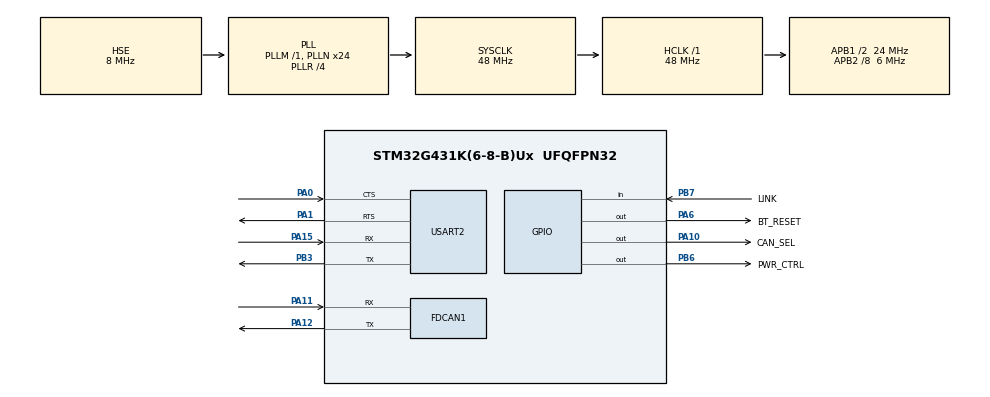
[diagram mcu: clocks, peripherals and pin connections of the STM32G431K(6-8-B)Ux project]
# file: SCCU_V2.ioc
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FDCAN1.AutoRetransmission=ENABLE
FDCAN1.CalculateBaudRateNominal=2000000
FDCAN1.CalculateTimeBitNominal=500
FDCAN1.CalculateTimeQuantumNominal=20.833333333333332
FDCAN1.ClockDivider=FDCAN_CLOCK_DIV4
FDCAN1.DataSyncJumpWidth=4
FDCAN1.DataTimeSeg1=18
FDCAN1.DataTimeSeg2=5
FDCAN1.NominalPrescaler=1
FDCAN1.NominalSyncJumpWidth=4
FDCAN1.NominalTimeSeg1=18
FDCAN1.NominalTimeSeg2=5
FDCAN1.StdFiltersNbr=4
Mcu.Family=STM32G4
Mcu.Name=STM32G431K(6-8-B)Ux
Mcu.Package=UFQFPN32
NVIC.FDCAN1_IT0_IRQn=true\:0\:0\:false\:false\:true\:true\:true\:true
NVIC.FDCAN1_IT1_IRQn=true\:0\:0\:false\:false\:true\:true\:true\:true
NVIC.PriorityGroup=NVIC_PRIORITYGROUP_4
NVIC.USART2_IRQn=true\:0\:0\:false\:false\:true\:true\:true\:true
PA0.Mode=CTS_RTS
PA0.Signal=USART2_CTS
PA1.Mode=CTS_RTS
PA1.Signal=USART2_RTS
PA10.GPIO_Label=CAN_SEL
PA10.Signal=GPIO_Output
PA11.Mode=FDCAN_Activate
PA11.Signal=FDCAN1_RX
PA12.Mode=FDCAN_Activate
PA12.Signal=FDCAN1_TX
PA15.Mode=Asynchronous
PA15.Signal=USART2_RX
PA2.Mode=SYS_WakeUp3
PA2.Signal=SYS_WKUP4
PA6.GPIO_Label=BT_RESET
PA6.Signal=GPIO_Output
PB3.Mode=Asynchronous
PB3.Signal=USART2_TX
PB6.GPIO_Label=PWR_CTRL
PB6.Signal=GPIO_Output
PB7.GPIO_Label=LINK
PB7.Signal=GPIO_Input
PF0-OSC_IN.Mode=HSE-External-Oscillator
PF0-OSC_IN.Signal=RCC_OSC_IN
PF1-OSC_OUT.Mode=HSE-External-Oscillator
PF1-OSC_OUT.Signal=RCC_OSC_OUT
ProjectManager.HeapSize=0x200
ProjectManager.StackSize=0x400
ProjectManager.TargetToolchain=STM32CubeIDE
RCC.ADC12Freq_Value=48000000
RCC.AHBFreq_Value=48000000
RCC.APB1CLKDivider=RCC_HCLK_DIV2
RCC.APB1Freq_Value=24000000
RCC.APB1TimFreq_Value=48000000
RCC.APB2CLKDivider=RCC_HCLK_DIV8
RCC.APB2Freq_Value=6000000
RCC.APB2TimFreq_Value=12000000
RCC.CortexFreq_Value=48000000
RCC.EXTERNAL_CLOCK_VALUE=12288000
RCC.FDCANCLockSelection=RCC_FDCANCLKSOURCE_PLL
RCC.HCLKFreq_Value=48000000
RCC.HSE_VALUE=8000000
RCC.HSI48_VALUE=48000000
RCC.HSI_VALUE=16000000
RCC.LSE_VALUE=32768
RCC.PLLN=24
RCC.PLLQ=RCC_PLLQ_DIV4
RCC.PLLR=RCC_PLLR_DIV4
RCC.PLLSourceVirtual=RCC_PLLSOURCE_HSE
RCC.PWR_Regulator_Voltage_Scale=PWR_REGULATOR_VOLTAGE_SCALE1
RCC.SYSCLKFreq_VALUE=48000000
RCC.SYSCLKSource=RCC_SYSCLKSOURCE_PLLCLK
RCC.USART2CLockSelection=RCC_USART2CLKSOURCE_SYSCLK
RCC.USBFreq_Value=48000000
RCC.VCOOutputFreq_Value=192000000
USART2.VirtualMode-Asynchronous=VM_ASYNC
VP_SYS_VS_DBSignals.Mode=DisableDeadBatterySignals
VP_WWDG_VS_WWDG.Mode=WWDG_Activate
WWDG.Counter=127
WWDG.Prescaler=WWDG_PRESCALER_128
WWDG.Window=127
board=custom

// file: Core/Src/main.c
/* USER CODE BEGIN Header */
/**
  ******************************************************************************
  * @file           : main.c
  * @brief          : Main program body
  ******************************************************************************
  * @attention
  *
  * Copyright (c) 2022 STMicroelectronics.
  * All rights reserved.
  *
  * This software is licensed under terms that can be found in the LICENSE file
  * in the root directory of this software component.
  * If no LICENSE file comes with this software, it is provided AS-IS.
  *
  ******************************************************************************
  */
/* USER CODE END Header */
#include "main.h"
#include "fdcan.h"
#include "usart.h"
#include "wwdg.h"
#include "gpio.h"

/* USER CODE BEGIN Includes */

#include "stdbool.h"
#include "../../Application/mainTask.h"
#include "../../Application/Modules/Modules.h"

/* USER CODE END Includes */

void SystemClock_Config(void);

int main(void)
{
  /* USER CODE BEGIN 1 */

  RTT_INIT("RTT init\n");

  /* USER CODE END 1 */

  /* MCU Configuration--------------------------------------------------------*/

  /* Reset of all peripherals, Initializes the Flash interface and the Systick. */
  HAL_Init();

  /* Configure the system clock */
  SystemClock_Config();

  /* Initialize all configured peripherals */
  MX_GPIO_Init();
  MX_FDCAN1_Init();
  MX_USART2_UART_Init();
  MX_WWDG_Init();

  /* Infinite loop */
  while (1)
  {

    /* USER CODE BEGIN 3 */
    mainTask();
  }
  /* USER CODE END 3 */
}

void SystemClock_Config(void)
{
  RCC_OscInitTypeDef RCC_OscInitStruct = {0};
  RCC_ClkInitTypeDef RCC_ClkInitStruct = {0};

  /** Configure the main internal regulator output voltage
  */
  HAL_PWREx_ControlVoltageScaling(PWR_REGULATOR_VOLTAGE_SCALE1);

  /** Initializes the RCC Oscillators according to the specified parameters
  * in the RCC_OscInitTypeDef structure.
  */
  RCC_OscInitStruct.OscillatorType = RCC_OSCILLATORTYPE_HSE;
  RCC_OscInitStruct.HSEState = RCC_HSE_ON;
  RCC_OscInitStruct.PLL.PLLState = RCC_PLL_ON;
  RCC_OscInitStruct.PLL.PLLSource = RCC_PLLSOURCE_HSE;
  RCC_OscInitStruct.PLL.PLLM = RCC_PLLM_DIV1;
  RCC_OscInitStruct.PLL.PLLN = 24;
  RCC_OscInitStruct.PLL.PLLP = RCC_PLLP_DIV2;
  RCC_OscInitStruct.PLL.PLLQ = RCC_PLLQ_DIV4;
  RCC_OscInitStruct.PLL.PLLR = RCC_PLLR_DIV4;
  if (HAL_RCC_OscConfig(&RCC_OscInitStruct) != HAL_OK)
  {
    Error_Handler();
  }

  /** Initializes the CPU, AHB and APB buses clocks
  */
  RCC_ClkInitStruct.ClockType = RCC_CLOCKTYPE_HCLK|RCC_CLOCKTYPE_SYSCLK
                              |RCC_CLOCKTYPE_PCLK1|RCC_CLOCKTYPE_PCLK2;
  RCC_ClkInitStruct.SYSCLKSource = RCC_SYSCLKSOURCE_PLLCLK;
  RCC_ClkInitStruct.AHBCLKDivider = RCC_SYSCLK_DIV1;
  RCC_ClkInitStruct.APB1CLKDivider = RCC_HCLK_DIV2;
  RCC_ClkInitStruct.APB2CLKDivider = RCC_HCLK_DIV8;

  if (HAL_RCC_ClockConfig(&RCC_ClkInitStruct, FLASH_LATENCY_1) != HAL_OK)
  {
    Error_Handler();
  }
}

void Error_Handler(void)
{
  __disable_irq();
  while (1)
  {
  }
}
